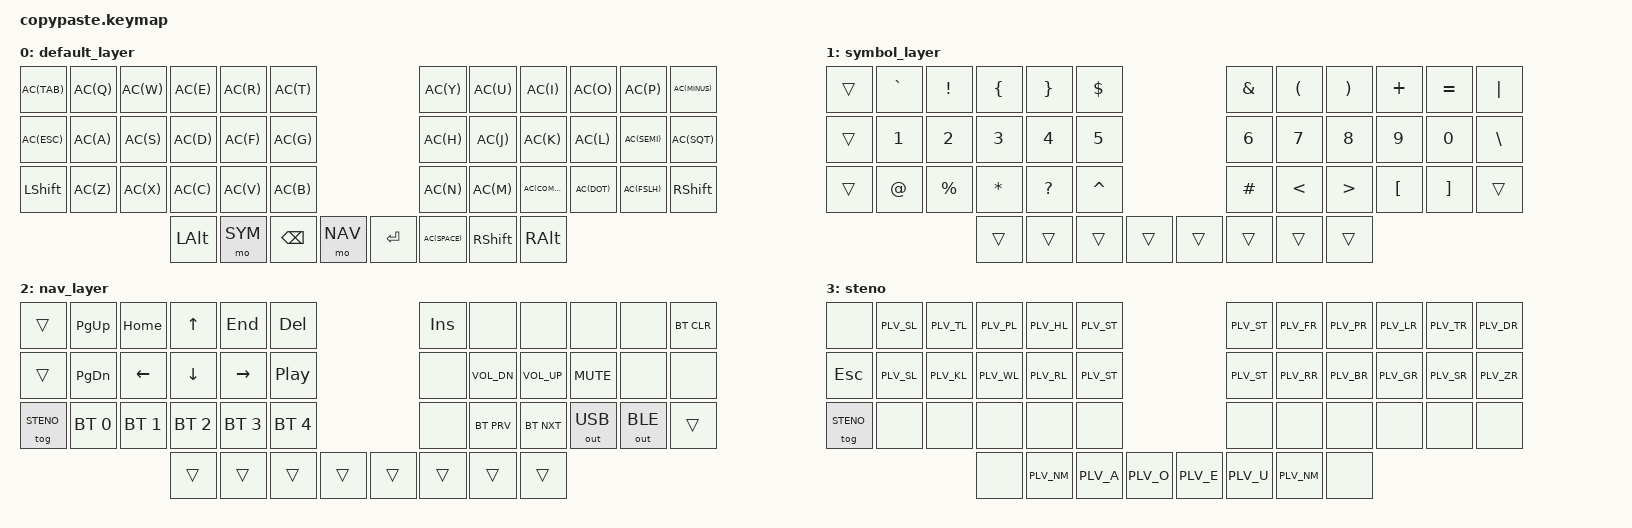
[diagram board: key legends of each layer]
#include <behaviors.dtsi>
#include <dt-bindings/zmk/keys.h>
#include <dt-bindings/zmk/bt.h>
#include <dt-bindings/zmk/outputs.h>

#define DEFAULT 0
#define SYM     1
#define NAV     2
#define STENO   3

#define AC(keycode) &ac LC(keycode) keycode    // hold key for ctrl + key macro

/ {
    behaviors {
        ac: auto_control {  
            compatible = "zmk,behavior-hold-tap";
            label = "AUTO_CONTROL";
            #binding-cells = <2>;
            flavor = "tap-preferred";
            tapping-term-ms = <600>;
            quick-tap-ms = <125>;
            global-quick-tap;
            bindings = <&kp>, <&kp>;
        };
    };

    keymap {
        compatible = "zmk,keymap";

        default_layer {
// --------------------------------------------------------------------------------------------------------------------------------------------------
// |   TAB   |    Q    |    W    |    E    |    R    |    T    |                        |    Y    |    U    |    I    |    O    |    P    |    -    |
// |   ESC   |    A    |    S    |    D    |    F    |    G    |                        |    H    |    J    |    K    |    L    |    ;    |    '    |
// |  SHIFT  |    Z    |    X    |    C    |    V    |    B    |                        |    N    |    M    |    ,    |    .    |    /    | R SHIFT |
//                               |  L ALT  |   SYM   |  BKSPC  |   NAV   |    | RETURN  |  SPACE  | R SHIFT |  R GUI  |
            bindings = <
    AC(TAB)     AC(Q)     AC(W)     AC(E)     AC(R)     AC(T)                              AC(Y)     AC(U)     AC(I)     AC(O)     AC(P)     AC(MINUS)
    AC(ESC)     AC(A)     AC(S)     AC(D)     AC(F)     AC(G)                              AC(H)     AC(J)     AC(K)     AC(L)     AC(SEMI)  AC(SQT)
    &kp LSHIFT  AC(Z)     AC(X)     AC(C)     AC(V)     AC(B)                              AC(N)     AC(M)     AC(COMMA) AC(DOT)   AC(FSLH)  &kp RSHIFT
                                    &kp LALT  &mo SYM  &kp BSPC &mo NAV        &kp RET    AC(SPACE) &kp RSHFT &kp RALT
            >;

            sensor-bindings = <&inc_dec_kp C_VOL_DN C_VOL_UP                                 &inc_dec_kp C_VOL_UP C_VOL_DN>;
        };

        symbol_layer {
// --------------------------------------------------------------------------------------------------------------------------------------------------
// |   TAB   |    `    |    !    |    {    |    }    |    $    |                        |    &    |    (    |    )    |    +    |    =    |    |    |
// |   ESC   |    1    |    2    |    3    |    4    |    5    |                        |    6    |    7    |    8    |    9    |    0    |    \    |
// |  SHIFT  |    @    |    %    |    *    |    ?    |    ^    |                        |    #    |    <    |    >    |    [    |    ]    | R SHIFT |
//                               |  L ALT  |   DEL   |  BKSPC  |   NAV   |    | RETURN  |  SPACE  | R SHIFT |  R ALT  |
            bindings = <
    &trans      &kp GRAVE &kp EXCL  &kp LBRC  &kp RBRC  &kp DLLR                           &kp AMPS  &kp LPAR  &kp RPAR  &kp PLUS  &kp EQUAL &kp PIPE
    &trans      &kp N1    &kp N2    &kp N3    &kp N4    &kp N5                             &kp N6    &kp N7    &kp N8    &kp N9    &kp N0    &kp BSLH
    &trans      &kp AT    &kp PRCNT &kp STAR  &kp QMARK &kp CARET                          &kp HASH  &kp LT    &kp GT    &kp LBKT  &kp RBKT  &trans
                                    &trans    &trans    &trans    &trans        &trans     &trans    &trans    &trans
            >;

            sensor-bindings = <&inc_dec_kp C_VOL_DN C_VOL_UP                                 &inc_dec_kp C_VOL_UP C_VOL_DN>;
        };

        nav_layer {
// --------------------------------------------------------------------------------------------------------------------------------------------------
// |   TAB   |  PUGUP  |  HOME   |   UP    |   END   |   DEL   |                        |   INS   |         |         |         |         |  BTCLR  |
// |   ESC   |  PGDWN  |  LEFT   |  DOWN   |  RIGHT  |PLAYPAUSE|                        |         |  VOLUP  |  VOLDN  |  MUTE   |         |         |
// |  SHIFT  | BTSEL 0 | BTSEL 1 | BTSEL 2 | BTSEL 3 | BTSEL 4 |                        |         |  BTPRV  |  BTNXT  | OUT_USB | OUT_BLE | R SHIFT |
//                               |  L ALT  |   DEL   |  BKSPC  |   NAV   |    | RETURN  |  SPACE  | R SHIFT |  R ALT  |
            bindings = <
    &trans      &kp PG_UP &kp HOME  &kp UP    &kp END   &kp DEL                            &kp INS   &none        &none        &none        &none        &bt BT_CLR
    &trans      &kp PG_DN &kp LEFT  &kp DOWN  &kp RIGHT &kp C_PP                           &none     &kp C_VOL_DN &kp C_VOL_UP &kp C_MUTE   &none        &none
   &tog STENO &bt BT_SEL 0 &bt BT_SEL 1 &bt BT_SEL 2 &bt BT_SEL 3 &bt BT_SEL 4  &none     &bt BT_PRV   &bt BT_NXT   &out OUT_USB &out OUT_BLE &trans
                                    &trans    &trans    &trans    &trans        &trans     &trans    &trans    &trans
            >;

            sensor-bindings = <&inc_dec_kp C_VOL_DN C_VOL_UP                                 &inc_dec_kp C_VOL_UP C_VOL_DN>;
        };

        steno {
// --------------------------------------------------------------------------------------------------------------------------------------------------
// |         |    S    |    T    |    P    |    H    |    *    |                        |    *    |    F    |    P    |    L    |    T    |    D    |
// |         |    S    |    K    |    W    |    R    |    *    |                        |    *    |    R    |    B    |    G    |    S    |    Z    |
// |         |         |         |         |         |         |                        |         |         |         |         |         |         |
//                               |         |    A    |    O    |   NAV   |    | RETURN  |  SPACE  | R SHIFT |  R ALT  |
            bindings = <
    &none     &kp PLV_SL &kp PLV_TL &kp PLV_PL &kp PLV_HL &kp PLV_ST                       &kp PLV_ST &kp PLV_FR &kp PLV_PR &kp PLV_LR &kp PLV_TR &kp PLV_DR
    &kp ESC   &kp PLV_SL &kp PLV_KL &kp PLV_WL &kp PLV_RL &kp PLV_ST                       &kp PLV_ST &kp PLV_RR &kp PLV_BR &kp PLV_GR &kp PLV_SR &kp PLV_ZR
   &tog STENO &none      &none      &none      &none      &none                            &none      &none      &none      &none      &none      &none 
                                    &none    &kp PLV_NM   &kp PLV_A &kp PLV_O     &kp PLV_E &kp PLV_U &kp PLV_NM &none
            >;

            sensor-bindings = <&inc_dec_kp C_VOL_DN C_VOL_UP                                 &inc_dec_kp C_VOL_UP C_VOL_DN>;
        };
    };    
};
